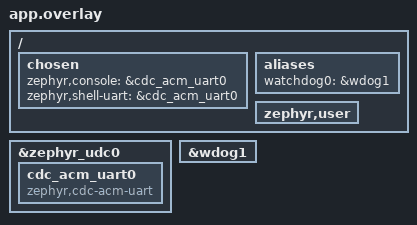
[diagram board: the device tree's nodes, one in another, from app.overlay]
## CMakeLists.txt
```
# Robotic Dog - legs firmware (Teensy 4.1, Zephyr RTOS, C++20)
cmake_minimum_required(VERSION 3.20.0)

find_package(Zephyr REQUIRED HINTS $ENV{ZEPHYR_BASE})
project(robotic_dog_legs)

# Which leg this build is for: 0=FR 1=FL 2=RR 3=RL (Conventions.md).
# scripts/02_build sets LEG_ID and the matching IP for every leg from
# scripts/legs.csv; include/config.hpp fails the build if the two disagree.
set(LEG_ID 0 CACHE STRING "Leg index 0..3 (FR FL RR RL)")

target_sources(app PRIVATE
    src/main.cpp
    src/shared.cpp
    src/hal.cpp
    src/rx_thread.cpp
    src/control_thread.cpp
    src/tx_thread.cpp
    src/supervisor_thread.cpp
)
target_include_directories(app PRIVATE include)
target_compile_definitions(app PRIVATE LEG_ID=${LEG_ID})
```

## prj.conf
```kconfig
# Robotic Dog - legs firmware configuration (Teensy 4.1, Zephyr v4.4)

# ---- C++20 --------------------------------------------------------------------
CONFIG_CPP=y
CONFIG_STD_CPP20=y
# Full C++ standard library: std::array, std::span, std::atomic, <algorithm>, ...
CONFIG_REQUIRES_FULL_LIBCPP=y

# ---- Floating point -----------------------------------------------------------
# The Teensy 4.1 board leaves the hardware FPU off; without this, float math is
# done in software. FPU_SHARING saves FPU registers when threads switch (the
# control and supervisor threads both use floats).
CONFIG_FPU=y
CONFIG_FPU_SHARING=y

# ---- Console over the Teensy's USB cable (shows up as a COM port) --------------
# printk() and log output go here. Same settings as Zephyr's cdc-acm-console
# snippet; app.overlay points the console at this USB serial port instead of the
# board's default console UART.
CONFIG_USB_DEVICE_STACK_NEXT=y
CONFIG_CDC_ACM_SERIAL_INITIALIZE_AT_BOOT=y
CONFIG_SERIAL=y
CONFIG_CONSOLE=y
CONFIG_UART_CONSOLE=y
CONFIG_UART_LINE_CTRL=y
# This USB port also carries the log output, so its own driver can't log (it
# would loop). Zephyr turns that log off anyway and warns at build time; saying
# it here silences the warning.
CONFIG_USBD_CDC_ACM_LOG_LEVEL_OFF=y

# ---- Networking: static IPv4, no DHCP (Conventions.md) -------------------------
# scripts/02_build builds one firmware per leg and overrides the address (and
# LEG_ID) from scripts/legs.csv. The default below is Front Right, LEG_ID 0.
CONFIG_NETWORKING=y
CONFIG_NET_IPV4=y
CONFIG_NET_IPV6=n
CONFIG_NET_UDP=y
CONFIG_NET_SOCKETS=y
CONFIG_NET_CONFIG_SETTINGS=y
CONFIG_NET_CONFIG_NEED_IPV4=y
CONFIG_NET_CONFIG_MY_IPV4_ADDR="192.168.1.11"
CONFIG_NET_CONFIG_MY_IPV4_NETMASK="255.255.255.0"
CONFIG_NET_DHCPV4=n
# Don't block boot waiting for the Ethernet link (default is 30 s). Zephyr
# assigns the static address whether or not the wait finishes, so with a
# static IP there is nothing to wait for: traffic flows once the link is up.
CONFIG_NET_CONFIG_INIT_TIMEOUT=0

# ---- Peripherals ---------------------------------------------------------------
# Until app.overlay enables a PWM node, CMake prints "No SOURCES given to Zephyr
# library: drivers__pwm". That warning is harmless.
CONFIG_ADC=y
CONFIG_PWM=y
CONFIG_WATCHDOG=y

# ---- Diagnostics ---------------------------------------------------------------
# INIT_STACKS + THREAD_STACK_INFO power the supervisor's stack-margin check on
# its four threads (k_thread_stack_space_get).
CONFIG_LOG=y
CONFIG_THREAD_STACK_INFO=y
CONFIG_INIT_STACKS=y

# ---- Stacks --------------------------------------------------------------------
CONFIG_MAIN_STACK_SIZE=4096
CONFIG_SYSTEM_WORKQUEUE_STACK_SIZE=2048
```

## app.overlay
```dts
/*
 * Robotic Dog - legs firmware devicetree overlay (Teensy 4.1)
 *
 * The only overlay this app uses. (Zephyr ignores app.overlay whenever a
 * boards/<board>.overlay exists, so keep everything in this one file.)
 *
 * 1. USB console: sends the Zephyr console (printk + logging) to a USB serial
 *    port on the Teensy's micro-USB connector instead of the board's default
 *    console UART (pin table: Zephyr's Teensy 4 board documentation).
 *    Same as Zephyr's cdc-acm-console snippet.
 * 2. Hardware watchdog for the supervisor's deadman (src/hal.cpp).
 * 3. Sensor and servo pins (TEMPLATE, switched off): src/hal.cpp reads them
 *    from the zephyr,user node below. While LEG_PINS_WIRED is 0, the HAL
 *    builds with stubbed sensors/outputs and logs a warning at boot.
 */

/* Set to 1 once the leg is wired like section 3 at the end of this file (edit
 * the pins there first if the real wiring differs), then do a clean build. */
#ifndef LEG_PINS_WIRED
#define LEG_PINS_WIRED 0
#endif

/ {
	chosen {
		zephyr,console = &cdc_acm_uart0;
		zephyr,shell-uart = &cdc_acm_uart0;
	};

	aliases {
		/* i.MX RT1062 WDOG2 (label wdog1) for the supervisor deadman. */
		watchdog0 = &wdog1;
	};

	zephyr,user {
#if LEG_PINS_WIRED
		/* io-channels: 6 ADC inputs - [0..2] position tilt, hip, knee;
		 *                             [3..5] current   tilt, hip, knee
		 * pwms:        3 servo outputs - tilt, hip, knee (50 Hz frame) */
		io-channels = <&adc1 7>, <&adc1 8>, <&adc1 12>,
			      <&adc1 11>, <&adc1 6>, <&adc1 5>;
		pwms = <&flexpwm2_pwm0 0 PWM_HZ(50) PWM_POLARITY_NORMAL>,
		       <&flexpwm2_pwm1 0 PWM_HZ(50) PWM_POLARITY_NORMAL>,
		       <&flexpwm2_pwm2 0 PWM_HZ(50) PWM_POLARITY_NORMAL>;
#endif
	};
};

&zephyr_udc0 {
	cdc_acm_uart0: cdc_acm_uart0 {
		compatible = "zephyr,cdc-acm-uart";
	};
};

/* Zephyr's SoC file ships both WDOGs disabled; the deadman needs this one on.
 * (Its driver accepts timeouts from 500 ms up, in 0.5 s steps.) */
&wdog1 {
	status = "okay";
};

/* ---- 3. Sensor and servo pins (example wiring) ------------------------------
 *
 * Sensors: Teensy pins 14-19 (A0-A5) = ADC1 inputs 7, 8, 12, 11, 6, 5. The
 *   numbers in io-channels and channel@N are ADC inputs, not Teensy pins.
 *   Pins 18/19 are also the I2C bus (Wire); if the leg needs I2C, use A6-A9
 *   instead (pins 20-23 = inputs 15, 0, 13, 14). Each input needs a channel@N
 *   node, or adc_channel_setup_dt() fails. This ADC only accepts gain 1, the
 *   internal reference and the default acquisition time.
 * Servos: Teensy pins 4, 5, 6 = FlexPWM2 submodules 0, 1, 2, output A
 *   (channel 0 in pwms). The teensy41 board routes no PWM pins, so each
 *   submodule needs its own pinctrl group.
 */
#if LEG_PINS_WIRED
#define LEG_ADC_INPUT(n)						\
	channel@n {							\
		reg = <n>;						\
		zephyr,gain = "ADC_GAIN_1";				\
		zephyr,reference = "ADC_REF_INTERNAL";			\
		zephyr,acquisition-time = <ADC_ACQ_TIME_DEFAULT>;	\
		zephyr,resolution = <12>;				\
	}

&adc1 {
	status = "okay";
	#address-cells = <1>;
	#size-cells = <0>;

	LEG_ADC_INPUT(7);	/* pin 14, A0: tilt position */
	LEG_ADC_INPUT(8);	/* pin 15, A1: hip position */
	LEG_ADC_INPUT(12);	/* pin 16, A2: knee position */
	LEG_ADC_INPUT(11);	/* pin 17, A3: tilt current */
	LEG_ADC_INPUT(6);	/* pin 18, A4: hip current */
	LEG_ADC_INPUT(5);	/* pin 19, A5: knee current */
};

&pinctrl {
	pinmux_servo_tilt: pinmux_servo_tilt {
		group0 {
			pinmux = <&iomuxc_gpio_emc_06_flexpwm2_pwma0>;	/* pin 4 */
			drive-strength = "r0-4";
			slew-rate = "slow";
			nxp,speed = "100-mhz";
		};
	};

	pinmux_servo_hip: pinmux_servo_hip {
		group0 {
			pinmux = <&iomuxc_gpio_emc_08_flexpwm2_pwma1>;	/* pin 5 */
			drive-strength = "r0-4";
			slew-rate = "slow";
			nxp,speed = "100-mhz";
		};
	};

	pinmux_servo_knee: pinmux_servo_knee {
		group0 {
			pinmux = <&iomuxc_gpio_b0_10_flexpwm2_pwma2>;	/* pin 6 */
			drive-strength = "r0-4";
			slew-rate = "slow";
			nxp,speed = "100-mhz";
		};
	};
};

&flexpwm2_pwm0 {
	status = "okay";
	pinctrl-0 = <&pinmux_servo_tilt>;
	pinctrl-names = "default";
};

&flexpwm2_pwm1 {
	status = "okay";
	pinctrl-0 = <&pinmux_servo_hip>;
	pinctrl-names = "default";
};

&flexpwm2_pwm2 {
	status = "okay";
	pinctrl-0 = <&pinmux_servo_knee>;
	pinctrl-names = "default";
};
#endif /* LEG_PINS_WIRED */
```

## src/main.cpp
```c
// Per-leg firmware entry point. The four threads (rx, control, tx,
// supervisor) are defined in their own files via K_THREAD_DEFINE and wait on
// init_done; main() brings up the hardware, starts the watchdog, then
// releases them. Boot-safe by construction: PWM outputs stay disabled until
// the master's ENABLE command arrives over the acked channel.
#include <zephyr/kernel.h>
#include <zephyr/logging/log.h>

#include "config.hpp"
#include "hal.hpp"
#include "shared.hpp"

LOG_MODULE_REGISTER(main, LOG_LEVEL_INF);

int main() {
  static constexpr const char* kLegName[4] = {"FR", "FL", "RR", "RL"};  // by LEG_ID
  LOG_INF("quadruped leg %s (id %u, ip %s) — Zephyr, 1 kHz control",
          kLegName[leg::cfg::kLegId], leg::cfg::kLegId, leg::cfg::kMyIp);

  leg::hal::disable_outputs();  // never twitch at boot

  if (!leg::hal::init())
    LOG_WRN("HAL degraded (see overlay warnings) — continuing for bench use");

  if (!leg::hal::wdt_start())
    LOG_ERR("hardware watchdog unavailable");

  // Release rx, control, tx, supervisor.
  for (int i = 0; i < 4; ++i) k_sem_give(&leg::init_done);

  LOG_INF("threads released; waiting for master heartbeat + ENABLE");
  return 0;
}
```

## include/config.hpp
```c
#pragma once
// Per-leg firmware tunables. Values mirror Conventions.md — change there first.
// LEG_ID and this leg's IP come from the build (scripts/02_build, using
// scripts/legs.csv): 0 = Front Right, 1 = Front Left, 2 = Rear Right,
// 3 = Rear Left.
#include <cstddef>
#include <cstdint>

namespace leg::cfg {

#ifndef LEG_ID
#define LEG_ID 0
#endif
inline constexpr std::uint8_t kLegId = LEG_ID;

// ---- network (static IPs; this leg's own IP is a Kconfig value) ------------
inline constexpr const char* kMasterIp   = "192.168.1.1";
inline constexpr std::uint16_t kPortRx   = 5005;  // we listen: setpoints, commands, heartbeat
inline constexpr std::uint16_t kPortTx   = 5006;  // master listens: telemetry, acks

#ifdef CONFIG_NET_CONFIG_MY_IPV4_ADDR
inline constexpr const char* kMyIp = CONFIG_NET_CONFIG_MY_IPV4_ADDR;

// Build sanity: leg N must use 192.168.1.(11 + N), on the master's subnet
// (Conventions.md). The build scripts pass LEG_ID and the IP together; if the
// two ever disagree, the build fails here instead of producing a leg that
// answers to the wrong address.
namespace detail {
constexpr int last_octet(const char* ip) {
  int v = 0;
  for (; *ip; ++ip) v = (*ip == '.') ? 0 : v * 10 + (*ip - '0');
  return v;
}
constexpr bool same_subnet24(const char* a, const char* b) {
  for (int dots = 0; *a && *b && *a == *b; ++a, ++b)
    if (*a == '.' && ++dots == 3) return true;
  return false;
}
}  // namespace detail
static_assert(detail::last_octet(kMyIp) == 11 + LEG_ID,
              "LEG_ID and IP disagree: leg N must use 192.168.1.(11 + N)");
static_assert(detail::same_subnet24(kMyIp, kMasterIp),
              "this leg's IP is not on the master's 192.168.1.x subnet");
#else
inline constexpr const char* kMyIp = "(not set)";
#endif

// ---- timing (diagram: control 1 kHz, TX ~500 Hz, supervisor tunable) -------
inline constexpr int kControlPeriodUs    = 1000;  // 1 kHz control tick
inline constexpr int kTelemetryPeriodMs  = 2;     // ~500 Hz
inline constexpr int kSupervisorDefaultMs = 50;   // tunable via command later
inline constexpr int kSupervisorMinMs     = 20;   // 50 Hz
inline constexpr int kSupervisorMaxMs     = 100;  // 10 Hz; must stay well under kWdtTimeoutMs

// ---- comms freshness (diagram: "comms fresh?") ------------------------------
inline constexpr std::uint32_t kSetpointTimeoutMs  = 50;   // hold/failsafe
inline constexpr std::uint32_t kHeartbeatTimeoutMs = 500;  // disarm

// Sender uptime (header t_ms) going backwards by more than this means the
// master restarted: sequence tracking resets instead of rejecting it.
inline constexpr std::uint32_t kRestartSlackMs = 1000;

// ---- watchdog ---------------------------------------------------------------
// Zephyr's i.MX WDOG driver rejects timeouts under 500 ms (0.5 s steps).
// The supervisor feeds every 20-100 ms, so 1 s leaves a 10x margin.
inline constexpr std::uint32_t kWdtTimeoutMs = 1000;

// ---- supervisor slow-check thresholds ---------------------------------------
inline constexpr float        kTrackingErrRad    = 0.5f;  // |pos - target| limit
inline constexpr std::int32_t kTrackingPersistMs = 500;   // must persist this long
inline constexpr std::size_t  kStackMarginBytes  = 256;   // min free stack headroom
inline constexpr int          kStackCheckEvery   = 20;    // supervisor passes (~1 s)

// ---- joints: calibration placeholders until the frame is measured ----------
// Conventions.md: master-side robot_config.yaml is the real source; the master
// will push these at ENABLE (SET_PARAM). These defaults keep v1 standalone.
struct JointCalib {
  float raw_at_zero;     // ADC counts at joint zero
  float rad_per_count;   // sign folded in
  float min_rad, max_rad;
  float current_limit_a; // hard per-tick limit
  float i2t_limit;       // supervisor sustained (A^2 * s above rated)
  float rated_a;
};
inline constexpr JointCalib kJoint[3] = {
    // tilt                                           (placeholders)
    {2048.f, 0.001534f, -0.6f, 0.6f, 3.0f, 4.0f, 1.5f},
    // hip
    {2048.f, 0.001534f, -1.2f, 1.2f, 4.0f, 6.0f, 2.0f},
    // knee
    {2048.f, 0.001534f, 0.0f, 2.4f, 4.0f, 6.0f, 2.0f},
};

// Current sensor: amps = (raw - zero) * kAmpsPerCount   (placeholder)
inline constexpr float kCurrentZeroCounts = 2048.f;
inline constexpr float kAmpsPerCount      = 0.004f;

// Servo mapping (v1: hobby servos, direct PWM; motors+PID later).
inline constexpr std::uint32_t kServoPeriodNs  = 20'000'000;  // 50 Hz frame
inline constexpr std::uint32_t kServoCenterNs  = 1'500'000;
inline constexpr float kServoNsPerRad = 1'000'000.0f / 1.5708f;  // ±90° -> ±1000 µs

}  // namespace leg::cfg
```

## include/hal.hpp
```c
#pragma once
// Hardware access: 3x position + 3x current ADC channels, 3x FlexPWM servo
// outputs. All devicetree bindings come from app.overlay; until
// the overlay has real pins, the stubs keep the logic building and testable.
#include <cstdint>

namespace leg::hal {

struct Sensors {
  float pos_rad[3];     // calibrated joint angles
  float current_a[3];   // calibrated joint currents
  bool  valid;
};

bool init();                       // ADC + PWM + watchdog devices ready?
Sensors read_sensors();            // one synchronous sample of all 6 channels

// v1 servo mode: write position targets straight to PWM (diagram:
// "servos now: direct · motors later: PID").
void write_servos(const float target_rad[3]);
void disable_outputs();            // zero pulse width = servos released

// Hardware watchdog (i.MX RT WDOG): supervisor feeds it, nobody else.
bool wdt_start();
void wdt_feed();

}  // namespace leg::hal
```

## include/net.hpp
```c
#pragma once
// Small zsock helpers shared by the RX and TX threads.
#include <zephyr/net/socket.h>

#include <cstdint>
#include <cstring>

#include "config.hpp"

namespace leg::net {

inline sockaddr_in master_endpoint() {
  sockaddr_in a{};
  a.sin_family = AF_INET;
  a.sin_port = htons(cfg::kPortTx);
  zsock_inet_pton(AF_INET, cfg::kMasterIp, &a.sin_addr);
  return a;
}

// Bound RX socket (we listen on :5005), or -1.
inline int make_rx_socket() {
  const int s = zsock_socket(AF_INET, SOCK_DGRAM, IPPROTO_UDP);
  if (s < 0) return -1;
  sockaddr_in local{};
  local.sin_family = AF_INET;
  local.sin_addr.s_addr = INADDR_ANY;
  local.sin_port = htons(cfg::kPortRx);
  if (zsock_bind(s, reinterpret_cast<sockaddr*>(&local), sizeof(local)) < 0) {
    zsock_close(s);
    return -1;
  }
  return s;
}

// Unbound TX socket for telemetry/acks toward the master.
inline int make_tx_socket() {
  return zsock_socket(AF_INET, SOCK_DGRAM, IPPROTO_UDP);
}

inline bool from_master(const sockaddr_in& from) {
  static const sockaddr_in master = master_endpoint();
  return std::memcmp(&from.sin_addr, &master.sin_addr, sizeof(in_addr)) == 0;
}

}  // namespace leg::net
```

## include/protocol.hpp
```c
#pragma once
// Wire protocol — byte-for-byte identical to the master's protocol.hpp
// (Conventions.md): little-endian packed structs, 14-byte header,
// CRC16-CCITT over header+payload, crc field last.
#include <cstdint>
#include <cstring>
#include <optional>
#include <span>

namespace leg::proto {

inline constexpr std::uint16_t kMagic   = 0xC0DE;  // fixed start marker
inline constexpr std::uint8_t  kVersion = 1;

enum class Type : std::uint8_t {
  Setpoint  = 1,
  Command   = 2,
  Heartbeat = 3,
  Telemetry = 4,
  Ack       = 5,
};

enum class Cmd : std::uint8_t {
  Enable      = 1,  // arm (refused while faults are latched)
  Disable     = 2,  // disarm
  ClearFaults = 3,  // operator acknowledged a fault; only honored while disarmed
};

#pragma pack(push, 1)
struct Header {
  std::uint16_t magic;
  std::uint8_t  version;
  std::uint8_t  type;
  std::uint8_t  leg_id;
  std::uint8_t  flags;
  std::uint32_t seq;
  std::uint32_t t_ms;
};
static_assert(sizeof(Header) == 14);

struct SetpointPacket {
  Header header;
  float  target_rad[3];
  std::uint16_t crc;
};
struct CommandPacket {
  Header header;
  std::uint8_t cmd;
  float        param;
  std::uint16_t crc;
};
struct HeartbeatPacket {
  Header header;
  std::uint8_t fsm_state;
  std::uint16_t crc;
};
struct TelemetryPacket {
  Header header;
  float pos_rad[3];
  float current_a[3];
  std::uint16_t fault_flags;
  std::uint16_t lost_packets;
  std::uint16_t crc_errors;
  std::uint8_t  armed;
  std::uint8_t  state;
  std::uint16_t crc;
};
struct AckPacket {
  Header header;
  std::uint32_t acked_seq;
  std::uint16_t crc;
};
#pragma pack(pop)

constexpr std::uint16_t crc16(std::span<const std::uint8_t> data) {
  std::uint16_t crc = 0xFFFF;
  for (std::uint8_t b : data) {
    crc ^= static_cast<std::uint16_t>(b) << 8;
    for (int i = 0; i < 8; ++i)
      crc = (crc & 0x8000) ? static_cast<std::uint16_t>((crc << 1) ^ 0x1021)
                           : static_cast<std::uint16_t>(crc << 1);
  }
  return crc;
}

template <typename P>
void seal(P& pkt) {
  auto* bytes = reinterpret_cast<std::uint8_t*>(&pkt);
  pkt.crc = crc16({bytes, sizeof(P) - sizeof(std::uint16_t)});
}

template <typename P>
std::optional<P> parse(std::span<const std::uint8_t> raw, Type expected) {
  if (raw.size() != sizeof(P)) return std::nullopt;
  P pkt;
  std::memcpy(&pkt, raw.data(), sizeof(P));
  if (pkt.header.magic != kMagic) return std::nullopt;
  if (pkt.header.version != kVersion) return std::nullopt;
  if (pkt.header.type != static_cast<std::uint8_t>(expected)) return std::nullopt;
  if (crc16(raw.first(sizeof(P) - sizeof(std::uint16_t))) != pkt.crc) return std::nullopt;
  return pkt;
}

}  // namespace leg::proto
```

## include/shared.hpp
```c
#pragma once
// The green boxes from the leg diagram — the ONLY places data crosses
// threads. Nothing on the hot path blocks or sleeps.
//
//   setpoint slot   spinlock copy, latest wins  RX  -> control
//   command queue   k_msgq, depth 8             RX  -> control
//   state snapshot  double buffer               control -> TX
//   health flag     atomic, set every tick      control -> supervisor
//   loss/CRC counters, t_hBeat, t_setpoint      atomics, RX writes
#include <zephyr/kernel.h>

#include <atomic>
#include <cstdint>

namespace leg {

// ---- setpoint slot (latest wins) -------------------------------------------
struct Setpoints {
  float target_rad[3]{};
};

// The RX thread writes; the control and supervisor threads read. On this
// single-core chip a k_spinlock just masks interrupts for the 12-byte copy, so
// no thread can be preempted halfway through it and nobody ever waits. (A
// seqlock is wrong here: if the 1 kHz tick preempted the RX thread mid-write,
// the higher-priority control thread spun forever on a write the RX thread
// could never get the CPU to finish.)
class SetpointSlot {
 public:
  void store(const Setpoints& s) {
    const k_spinlock_key_t key = k_spin_lock(&lock_);
    value_ = s;
    k_spin_unlock(&lock_, key);
  }
  Setpoints load() const {
    const k_spinlock_key_t key = k_spin_lock(&lock_);
    const Setpoints out = value_;
    k_spin_unlock(&lock_, key);
    return out;
  }

 private:
  mutable k_spinlock lock_{};  // zero-initialized = unlocked
  Setpoints value_{};
};

// ---- command queue (k_msgq is defined in shared.cpp, depth 8) --------------
struct CmdMsg {
  std::uint8_t  cmd;    // proto::Cmd
  float         param;
  std::uint32_t seq;    // echoed in the ACK
};
extern k_msgq cmd_queue;

// ---- state snapshot (double buffer: control writes, TX reads) --------------
struct Snapshot {
  float pos_rad[3]{};
  float current_a[3]{};
  std::uint16_t fault_flags{};
  std::uint8_t  armed{};
  std::uint8_t  state{};   // LegState below
};

class SnapshotBuffer {
 public:
  void publish(const Snapshot& s) {
    const int next = 1 - active_.load(std::memory_order_relaxed);
    buf_[next] = s;
    active_.store(next, std::memory_order_release);
  }
  Snapshot read() const {
    return buf_[active_.load(std::memory_order_acquire)];
  }

 private:
  Snapshot buf_[2]{};
  std::atomic<int> active_{0};
};

// ---- timestamps ------------------------------------------------------------
// Milliseconds from k_uptime_get_32(). 32-bit on purpose: the Cortex-M7 has no
// 64-bit atomics, so std::atomic<int64_t> fails to link (__atomic_load_8).
// Unsigned subtraction keeps ages right across the 49.7-day wraparound; always
// go through age_ms() so the math stays 32-bit unsigned.
constexpr std::uint32_t age_ms(std::uint32_t now, std::uint32_t then) {
  return now - then;
}
// "Never received": starts about 24 days in the past, so nothing is fresh
// until the first packet arrives.
inline constexpr std::uint32_t kNeverMs = 0x8000'0000u;

// ---- atomics shared across threads -----------------------------------------
struct SharedState {
  SetpointSlot   setpoints;
  SnapshotBuffer snapshot;

  std::atomic<std::uint32_t> t_setpoint_ms{kNeverMs};  // last valid setpoint
  std::atomic<std::uint32_t> t_hbeat_ms{kNeverMs};     // last heartbeat (t_hBeat)
  std::atomic<bool>         armed{false};
  std::atomic<bool>         health_flag{false};         // control sets, supervisor clears
  std::atomic<std::uint16_t> fault_flags{0};            // supervisor-latched faults

  // link stats: RX writes, TX reports, supervisor watches the trend
  std::atomic<std::uint16_t> lost_packets{0};
  std::atomic<std::uint16_t> crc_errors{0};
  std::atomic<std::uint32_t> rx_ok{0};

  std::atomic<std::int32_t>  supervisor_period_ms{0};   // 0 -> use default
};
extern SharedState g;

// Startup gate: main() gives this 4 times once HAL + watchdog are up.
extern k_sem init_done;

// The four application threads (K_THREAD_DEFINE in their own .cpp files).
// The supervisor's stack check watches these.
extern const k_tid_t rx_tid;
extern const k_tid_t control_tid;
extern const k_tid_t tx_tid;
extern const k_tid_t supervisor_tid;

// Fault bits (telemetry fault_flags)
inline constexpr std::uint16_t kFaultOverCurrent = 1u << 0;
inline constexpr std::uint16_t kFaultRange       = 1u << 1;
inline constexpr std::uint16_t kFaultCommsLost   = 1u << 2;
inline constexpr std::uint16_t kFaultI2t         = 1u << 3;
inline constexpr std::uint16_t kFaultTracking    = 1u << 4;
inline constexpr std::uint16_t kFaultStack       = 1u << 5;

enum class LegState : std::uint8_t { Disarmed = 0, Armed = 1, Failsafe = 2 };

}  // namespace leg
```

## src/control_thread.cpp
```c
// Diagram: "Control thread (1 kHz, prio high)".
//   k_sem_take(tick) <- k_timer ISR @ 1 kHz
//   read sensors -> copy setpoints + drain commands -> comms fresh?
//   (setpoint < 50 ms, heartbeat < 500 ms) -> failsafe/disarm
//   per-tick checks (armed? I > limit? pos in range?) -> targets -> FlexPWM
//   publish snapshot + set health flag -> loop
#include <zephyr/kernel.h>
#include <zephyr/logging/log.h>

#include <algorithm>

#include "config.hpp"
#include "hal.hpp"
#include "protocol.hpp"
#include "shared.hpp"

LOG_MODULE_REGISTER(control, LOG_LEVEL_INF);

namespace leg {
namespace {

K_SEM_DEFINE(tick_sem, 0, 1);

void tick_isr(k_timer*) { k_sem_give(&tick_sem); }  // ISR: capture + signal only
K_TIMER_DEFINE(tick_timer, tick_isr, nullptr);

// Returns true when an ENABLE armed the leg this tick, so the caller can
// re-seed targets from the measured pose (motionless arming).
bool drain_commands() {
  bool just_armed = false;
  CmdMsg msg;
  while (k_msgq_get(&cmd_queue, &msg, K_NO_WAIT) == 0) {
    switch (static_cast<proto::Cmd>(msg.cmd)) {
      case proto::Cmd::Enable:
        // Faults clear only through an operator-acknowledged CLEAR_FAULTS,
        // never as a side effect of arming.
        if (const auto f = g.fault_flags.load(); f != 0) {
          LOG_WRN("ENABLE refused: latched faults 0x%04x (cmd seq %u)", f, msg.seq);
          break;
        }
        if (!g.armed.exchange(true)) just_armed = true;
        LOG_INF("ENABLE (cmd seq %u)", msg.seq);
        break;
      case proto::Cmd::Disable:
        g.armed.store(false);
        LOG_INF("DISABLE (cmd seq %u)", msg.seq);
        break;
      case proto::Cmd::ClearFaults:
        if (g.armed.load()) {
          LOG_WRN("CLEAR_FAULTS ignored while armed (cmd seq %u)", msg.seq);
          break;
        }
        g.fault_flags.store(0);  // a still-present cause re-latches on its next check
        LOG_INF("faults cleared by operator (cmd seq %u)", msg.seq);
        break;
    }
  }
  return just_armed;
}

void control_main(void*, void*, void*) {
  k_sem_take(&init_done, K_FOREVER);
  k_timer_start(&tick_timer, K_USEC(cfg::kControlPeriodUs),
                K_USEC(cfg::kControlPeriodUs));
  LOG_INF("control loop at %d us", cfg::kControlPeriodUs);

  float targets[3] = {0.f, 0.f, 0.f};  // last good targets (hold on brief gaps)

  for (;;) {
    k_sem_take(&tick_sem, K_FOREVER);
    const std::uint32_t now_ms = k_uptime_get_32();

    // 1. sensors: 3x position, 3x current
    const hal::Sensors s = hal::read_sensors();

    // 2. latest setpoints + any pending commands
    const Setpoints sp = g.setpoints.load();
    const bool just_armed = drain_commands();

    // Motionless arming: the instant ENABLE lands, seed targets from the
    // MEASURED joint positions so the servos hold where the leg already is
    // instead of snapping to the zero pose. The master's stand-up ramp also
    // starts from the reported pose, so the first setpoints match this.
    if (just_armed && s.valid) {
      targets[0] = s.pos_rad[0];
      targets[1] = s.pos_rad[1];
      targets[2] = s.pos_rad[2];
    }

    // 3. comms fresh?  setpoint < 50 ms (hold), heartbeat < 500 ms (disarm)
    const bool sp_fresh =
        age_ms(now_ms, g.t_setpoint_ms.load()) < cfg::kSetpointTimeoutMs;
    const bool hb_fresh =
        age_ms(now_ms, g.t_hbeat_ms.load()) < cfg::kHeartbeatTimeoutMs;

    bool armed = g.armed.load();
    LegState state = armed ? LegState::Armed : LegState::Disarmed;

    if (armed && !hb_fresh) {           // master silent: failsafe / disarm
      g.armed.store(false);
      armed = false;
      state = LegState::Failsafe;
      g.fault_flags.fetch_or(kFaultCommsLost);
      LOG_WRN("heartbeat lost -> disarm");
    } else if (armed && sp_fresh) {
      targets[0] = sp.target_rad[0];
      targets[1] = sp.target_rad[1];
      targets[2] = sp.target_rad[2];
    }
    // armed && !sp_fresh: hold last targets (brief gap costs one stale tick)

    // 4. per-tick checks: cheap compares only — the expensive ones live in
    //    the supervisor. Range clamps the target; overcurrent latches fault.
    std::uint16_t faults = 0;
    for (int i = 0; i < 3; ++i) {
      const auto& c = cfg::kJoint[i];
      if (targets[i] < c.min_rad || targets[i] > c.max_rad) {
        targets[i] = std::clamp(targets[i], c.min_rad, c.max_rad);
        faults |= kFaultRange;
      }
      if (s.valid && s.current_a[i] > c.current_limit_a)
        faults |= kFaultOverCurrent;
    }
    if (faults & kFaultOverCurrent) {   // hard limit: cut now, stay cut
      g.armed.store(false);
      armed = false;
      g.fault_flags.fetch_or(faults);
    }

    // 5. outputs: servos now (direct), motors later (PID goes right here)
    if (armed) hal::write_servos(targets);
    else hal::disable_outputs();

    // 6. publish snapshot for TX, set health flag for the supervisor
    Snapshot snap{};
    for (int i = 0; i < 3; ++i) {
      snap.pos_rad[i] = s.pos_rad[i];
      snap.current_a[i] = s.current_a[i];
    }
    snap.fault_flags = g.fault_flags.load() | faults;
    snap.armed = armed ? 1 : 0;
    snap.state = static_cast<std::uint8_t>(state);
    g.snapshot.publish(snap);
    g.health_flag.store(true);          // supervisor feeds WDOG only on this
  }
}

}  // namespace

// Outside the anonymous namespace so shared.hpp's control_tid names this thread.
K_THREAD_DEFINE(control_tid, 4096, control_main, NULL, NULL, NULL, 2, 0, 0);

}  // namespace leg
```

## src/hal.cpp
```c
// Devicetree-backed HAL. Channels/pins come from the zephyr,user node in
// app.overlay. Guarded so the code still compiles while the
// overlay is a template — stubbed paths log once and return safe values.
#include "hal.hpp"

#include <zephyr/device.h>
#include <zephyr/drivers/adc.h>
#include <zephyr/drivers/pwm.h>
#include <zephyr/drivers/watchdog.h>
#include <zephyr/kernel.h>
#include <zephyr/logging/log.h>

#include <algorithm>

#include "config.hpp"

LOG_MODULE_REGISTER(hal, LOG_LEVEL_INF);

namespace leg::hal {
namespace {

#define USER_NODE DT_PATH(zephyr_user)

#if DT_NODE_HAS_PROP(USER_NODE, io_channels)
constexpr bool kHasAdc = true;
const adc_dt_spec adc_ch[6] = {
    ADC_DT_SPEC_GET_BY_IDX(USER_NODE, 0), ADC_DT_SPEC_GET_BY_IDX(USER_NODE, 1),
    ADC_DT_SPEC_GET_BY_IDX(USER_NODE, 2), ADC_DT_SPEC_GET_BY_IDX(USER_NODE, 3),
    ADC_DT_SPEC_GET_BY_IDX(USER_NODE, 4), ADC_DT_SPEC_GET_BY_IDX(USER_NODE, 5),
};
#else
constexpr bool kHasAdc = false;
#endif

#if DT_NODE_HAS_PROP(USER_NODE, pwms)
constexpr bool kHasPwm = true;
const pwm_dt_spec servo[3] = {
    PWM_DT_SPEC_GET_BY_IDX(USER_NODE, 0),
    PWM_DT_SPEC_GET_BY_IDX(USER_NODE, 1),
    PWM_DT_SPEC_GET_BY_IDX(USER_NODE, 2),
};
#else
constexpr bool kHasPwm = false;
#endif

// A node can exist but be disabled (Zephyr ships both i.MX WDOGs disabled),
// and DEVICE_DT_GET on a disabled node fails at link time — so require
// status "okay", which the overlay sets.
#define LEG_HAS_WDT DT_NODE_HAS_STATUS(DT_ALIAS(watchdog0), okay)

#if LEG_HAS_WDT
const device* wdt_dev = DEVICE_DT_GET(DT_ALIAS(watchdog0));
int wdt_channel = -1;
#endif

#if DT_NODE_HAS_PROP(USER_NODE, io_channels)
float counts_to_rad(int joint, float raw) {
  const auto& c = cfg::kJoint[joint];
  return (raw - c.raw_at_zero) * c.rad_per_count;
}
#endif

}  // namespace

bool init() {
  bool ok = true;
#if DT_NODE_HAS_PROP(USER_NODE, io_channels)
  for (const auto& ch : adc_ch) {
    if (!adc_is_ready_dt(&ch)) { LOG_ERR("ADC channel not ready"); ok = false; }
    else if (adc_channel_setup_dt(&ch) != 0) {
      LOG_ERR("ADC channel %u setup failed (check its channel@ node in app.overlay)",
              ch.channel_id);
      ok = false;
    }
  }
#else
  LOG_WRN("overlay has no io-channels: sensor reads are STUBBED");
#endif
#if DT_NODE_HAS_PROP(USER_NODE, pwms)
  for (const auto& s : servo)
    if (!pwm_is_ready_dt(&s)) { LOG_ERR("PWM channel not ready"); ok = false; }
#else
  LOG_WRN("overlay has no pwms: servo outputs are STUBBED");
#endif
  return ok;
}

Sensors read_sensors() {
  Sensors out{};
#if DT_NODE_HAS_PROP(USER_NODE, io_channels)
  std::int16_t sample = 0;
  adc_sequence seq{};  // adc_sequence_init_dt fills channels/resolution
  seq.buffer = &sample;
  seq.buffer_size = sizeof(sample);
  for (int i = 0; i < 6; ++i) {
    adc_sequence_init_dt(&adc_ch[i], &seq);
    if (adc_read(adc_ch[i].dev, &seq) != 0) return out;  // valid stays false
    const float raw = static_cast<float>(sample);
    if (i < 3) out.pos_rad[i] = counts_to_rad(i, raw);
    else out.current_a[i - 3] = (raw - cfg::kCurrentZeroCounts) * cfg::kAmpsPerCount;
  }
  out.valid = true;
#else
  out.valid = true;  // stub: zeros, so the state machine still runs on a bench
#endif
  return out;
}

void write_servos(const float target_rad[3]) {
#if DT_NODE_HAS_PROP(USER_NODE, pwms)
  for (int i = 0; i < 3; ++i) {
    const float ns = static_cast<float>(cfg::kServoCenterNs) +
                     target_rad[i] * cfg::kServoNsPerRad;
    const auto pulse = static_cast<std::uint32_t>(
        std::clamp(ns, 500'000.0f, 2'500'000.0f));
    pwm_set_pulse_dt(&servo[i], pulse);
  }
#else
  ARG_UNUSED(target_rad);
#endif
}

void disable_outputs() {
#if DT_NODE_HAS_PROP(USER_NODE, pwms)
  for (const auto& s : servo) pwm_set_pulse_dt(&s, 0);  // released, not driven
#endif
}

bool wdt_start() {
#if LEG_HAS_WDT
  if (!device_is_ready(wdt_dev)) { LOG_ERR("watchdog not ready"); return false; }
  wdt_timeout_cfg tcfg{
      .window = {.min = 0, .max = cfg::kWdtTimeoutMs},
      .callback = nullptr,
      .flags = WDT_FLAG_RESET_SOC,
  };
  wdt_channel = wdt_install_timeout(wdt_dev, &tcfg);
  if (wdt_channel < 0) {
    LOG_ERR("wdt_install_timeout(%u ms) failed: %d", cfg::kWdtTimeoutMs, wdt_channel);
    return false;
  }
  const int rc = wdt_setup(wdt_dev, WDT_OPT_PAUSE_HALTED_BY_DBG);
  if (rc != 0) {
    LOG_ERR("wdt_setup failed: %d", rc);
    return false;
  }
  LOG_INF("hardware watchdog armed: %u ms", cfg::kWdtTimeoutMs);
  return true;
#else
  LOG_WRN("watchdog0 alias missing or disabled: HW watchdog OFF (bench mode)");
  return true;
#endif
}

void wdt_feed() {
#if LEG_HAS_WDT
  if (wdt_channel >= 0) ::wdt_feed(wdt_dev, wdt_channel);
#endif
}

}  // namespace leg::hal
```

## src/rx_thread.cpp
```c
// Diagram: "Net RX thread (prio mid)".
//   recvfrom(:5005) -> magic+CRC ok? -> seq > last_seq? -> count gaps ->
//   dispatch: setpoints -> slot, commands -> k_msgq (+ACK), heartbeat -> t_hBeat
//
// Two rules keep the sequence check from deafening the leg:
//   * Restart-aware: if the master's uptime (header t_ms) jumps backwards,
//     the master restarted and sequence tracking starts over.
//   * Commands are never dropped as "old": a retransmitted command carries
//     its original sequence number, which newer setpoints may already have
//     overtaken. Commands are de-duplicated by their own sequence instead.
#include <zephyr/kernel.h>
#include <zephyr/logging/log.h>
#include <zephyr/net/socket.h>

#include <cstdint>
#include <span>

#include "config.hpp"
#include "net.hpp"
#include "protocol.hpp"
#include "shared.hpp"

LOG_MODULE_REGISTER(rx, LOG_LEVEL_INF);

namespace leg {
namespace {

std::uint32_t last_seq = 0;        // newest master packet seen this session
std::uint32_t last_cmd_seq = 0;    // newest command already queued
std::uint32_t last_master_t = 0;   // newest master uptime seen (ms)
bool          have_master_t = false;
std::uint32_t ack_seq = 0;

void send_ack(int tx_sock, std::uint32_t acked, std::uint32_t t_ms) {
  proto::AckPacket p{
      .header = {.magic = proto::kMagic,
                 .version = proto::kVersion,
                 .type = static_cast<std::uint8_t>(proto::Type::Ack),
                 .leg_id = cfg::kLegId,
                 .flags = 0,
                 .seq = ++ack_seq,
                 .t_ms = t_ms},
      .acked_seq = acked,
      .crc = 0};
  proto::seal(p);
  const sockaddr_in master = net::master_endpoint();
  zsock_sendto(tx_sock, &p, sizeof(p), 0,
               reinterpret_cast<const sockaddr*>(&master), sizeof(master));
}

// Every header carries the sender's uptime. A backwards jump larger than
// kRestartSlackMs means a new master session: forget the old sequence
// numbers instead of rejecting the new session for as long as the old ran.
void track_master_session(const proto::Header& h) {
  if (have_master_t && h.t_ms + cfg::kRestartSlackMs < last_master_t) {
    LOG_WRN("master restart detected (uptime %u -> %u ms): sequence tracking reset",
            last_master_t, h.t_ms);
    last_seq = 0;
    last_cmd_seq = 0;
    last_master_t = h.t_ms;
  } else if (!have_master_t || h.t_ms > last_master_t) {
    last_master_t = h.t_ms;
  }
  have_master_t = true;
}

// Records seq if it is the newest seen, counting any gap as lost packets.
// Returns false for duplicates and reordered (older) packets.
bool record_seq(std::uint32_t seq) {
  if (last_seq != 0 && seq <= last_seq) return false;
  if (last_seq != 0 && seq > last_seq + 1)
    g.lost_packets.fetch_add(static_cast<std::uint16_t>(seq - last_seq - 1));
  last_seq = seq;
  return true;
}

void dispatch(std::span<const std::uint8_t> raw, int tx_sock) {
  const std::uint32_t now_ms = k_uptime_get_32();

  // Streams (setpoints, heartbeats): newest wins, older packets are stale.
  if (auto p = proto::parse<proto::SetpointPacket>(raw, proto::Type::Setpoint)) {
    if (p->header.leg_id != cfg::kLegId) return;
    track_master_session(p->header);
    if (!record_seq(p->header.seq)) return;
    g.setpoints.store(Setpoints{{p->target_rad[0], p->target_rad[1], p->target_rad[2]}});
    g.t_setpoint_ms.store(now_ms);
    g.rx_ok.fetch_add(1);
    return;
  }
  if (auto p = proto::parse<proto::HeartbeatPacket>(raw, proto::Type::Heartbeat)) {
    if (p->header.leg_id != cfg::kLegId) return;
    track_master_session(p->header);
    if (!record_seq(p->header.seq)) return;
    g.t_hbeat_ms.store(now_ms);   // t_hBeat: master is alive (any FSM state)
    g.rx_ok.fetch_add(1);
    return;
  }

  // Commands: never rejected as old; de-duplicated by command sequence.
  if (auto p = proto::parse<proto::CommandPacket>(raw, proto::Type::Command)) {
    if (p->header.leg_id != cfg::kLegId) return;
    track_master_session(p->header);
    const std::uint32_t seq = p->header.seq;
    record_seq(seq);  // loss statistics only
    if (seq <= last_cmd_seq) {          // retransmit of a command already queued
      send_ack(tx_sock, seq, now_ms);   // our earlier ACK was lost: re-ACK
      return;
    }
    CmdMsg msg{.cmd = p->cmd, .param = p->param, .seq = seq};
    if (k_msgq_put(&cmd_queue, &msg, K_NO_WAIT) != 0) {
      LOG_WRN("command queue full: cmd %u not ACKed, master will retry", msg.cmd);
      return;
    }
    last_cmd_seq = seq;
    send_ack(tx_sock, seq, now_ms);     // ACK only once the command is queued
    g.rx_ok.fetch_add(1);
    return;
  }
  g.crc_errors.fetch_add(1);  // wrong magic/CRC/size: drop, count
}

void rx_main(void*, void*, void*) {
  k_sem_take(&init_done, K_FOREVER);

  const int rx = net::make_rx_socket();
  const int tx = net::make_tx_socket();
  if (rx < 0 || tx < 0) {
    LOG_ERR("socket setup failed (rx=%d tx=%d)", rx, tx);
    return;
  }
  LOG_INF("listening on :%u as leg %u", cfg::kPortRx, cfg::kLegId);

  std::uint8_t buf[128];
  for (;;) {
    sockaddr_in from{};
    socklen_t from_len = sizeof(from);
    const auto n = zsock_recvfrom(rx, buf, sizeof(buf), 0,
                                  reinterpret_cast<sockaddr*>(&from), &from_len);
    if (n <= 0) continue;
    if (!net::from_master(from)) continue;  // only the master may command us
    dispatch({buf, static_cast<std::size_t>(n)}, tx);
  }
}

}  // namespace

// Outside the anonymous namespace so shared.hpp's rx_tid names this thread.
K_THREAD_DEFINE(rx_tid, 4096, rx_main, NULL, NULL, NULL, 5, 0, 0);

}  // namespace leg
```

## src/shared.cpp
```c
// Definitions of the shared objects declared in shared.hpp.
#include "shared.hpp"

namespace leg {

// Diagram: "command queue — k_msgq, depth 8".
K_MSGQ_DEFINE(cmd_queue, sizeof(CmdMsg), 8, 4);

SharedState g;

// Gate: main() releases the worker threads once HAL + watchdog are up.
K_SEM_DEFINE(init_done, 0, 4);

}  // namespace leg
```

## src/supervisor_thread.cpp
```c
// Diagram: "Supervisor (10–50 Hz, tunable)".
//   k_sleep(cfg.period) -> slow checks (I²t window, tracking error,
//   link loss trend, stack margins) -> on fault: flag telemetry, disarm ->
//   health flag fresh? -> feed WDOG / don't feed -> HW reset
#include <zephyr/kernel.h>
#include <zephyr/logging/log.h>

#include <algorithm>
#include <cmath>

#include "config.hpp"
#include "hal.hpp"
#include "shared.hpp"

LOG_MODULE_REGISTER(supervisor, LOG_LEVEL_INF);

namespace leg {
namespace {

void supervisor_main(void*, void*, void*) {
  k_sem_take(&init_done, K_FOREVER);
  LOG_INF("supervisor at %d ms (tunable)", cfg::kSupervisorDefaultMs);

  float i2t_acc[3] = {0.f, 0.f, 0.f};
  std::uint16_t last_lost = 0;
  std::int32_t tracking_err_ms = 0;
  [[maybe_unused]] int pass = 0;

  for (;;) {
    // Clamped to 10-50 Hz so no tuned value can starve the watchdog.
    const std::int32_t override_ms = g.supervisor_period_ms.load();
    const std::int32_t period_ms =
        std::clamp(override_ms > 0 ? override_ms : cfg::kSupervisorDefaultMs,
                   cfg::kSupervisorMinMs, cfg::kSupervisorMaxMs);
    k_sleep(K_MSEC(period_ms));
    const float dt = static_cast<float>(period_ms) / 1000.f;

    const Snapshot snap = g.snapshot.read();
    std::uint16_t faults = 0;

    // I²t window: a motor survives brief spikes but not sustained overload.
    for (int i = 0; i < 3; ++i) {
      const auto& c = cfg::kJoint[i];
      const float i2 = snap.current_a[i] * snap.current_a[i];
      const float rated2 = c.rated_a * c.rated_a;
      i2t_acc[i] = std::max(0.f, i2t_acc[i] + (i2 - rated2) * dt);
      if (i2t_acc[i] > c.i2t_limit) faults |= kFaultI2t;
    }

    // Tracking error must PERSIST (diagram: "tracking error persists?") —
    // one bad sample during a foot strike is normal; half a second of the
    // joint ignoring its target means jammed or broken.
    const Setpoints sp = g.setpoints.load();
    bool erring = false;
    if (snap.armed) {
      for (int i = 0; i < 3; ++i)
        if (std::abs(snap.pos_rad[i] - sp.target_rad[i]) > cfg::kTrackingErrRad)
          erring = true;
    }
    tracking_err_ms = erring ? tracking_err_ms + period_ms : 0;
    if (tracking_err_ms >= cfg::kTrackingPersistMs) faults |= kFaultTracking;

    // Link loss trend: on a healthy dedicated switch this stays zero, so a
    // rising counter is a bug/cable to investigate, not noise to tolerate.
    const std::uint16_t lost = g.lost_packets.load();
    if (lost != last_lost)
      LOG_WRN("packet loss rising: %u total", lost);
    last_lost = lost;

    // Stack margins (diagram: "stack margins"): about once a second, flag any
    // of OUR four threads with less than kStackMarginBytes of stack left.
    // Zephyr's own threads are left out on purpose: it sizes them tightly
    // (the idle thread has 320 bytes in total), so a fixed margin would fault
    // a healthy leg, and the MPU stack guard (CONFIG_MPU_STACK_GUARD) already
    // catches a real overflow in any thread. The scan runs with interrupts
    // enabled, so it cannot delay the 1 kHz control tick.
#ifdef CONFIG_INIT_STACKS
    if (++pass % cfg::kStackCheckEvery == 0) {
      static constexpr const char* kName[] = {"rx", "control", "tx", "supervisor"};
      const k_tid_t tids[] = {rx_tid, control_tid, tx_tid, supervisor_tid};
      for (int i = 0; i < 4; ++i) {
        std::size_t unused = 0;
        if (k_thread_stack_space_get(tids[i], &unused) == 0 &&
            unused < cfg::kStackMarginBytes) {
          faults |= kFaultStack;
          LOG_ERR("%s thread stack nearly full: %u bytes left", kName[i],
                  static_cast<unsigned>(unused));
        }
      }
    }
#endif

    if (faults) {
      g.fault_flags.fetch_or(faults);   // flagged in telemetry
      g.armed.store(false);             // derate/disable the leg
      LOG_ERR("supervisor fault 0x%04x -> disarm", faults);
    }

    // Deadman: feed the hardware watchdog ONLY if the control thread set its
    // health flag since our last pass. A hung control loop starves the WDOG
    // and the i.MX RT resets — a reset leg is safer than a frozen one.
    if (g.health_flag.exchange(false)) {
      hal::wdt_feed();
    } else {
      LOG_ERR("control thread unresponsive: letting WDOG starve");
      // no feed -> hardware reset within cfg::kWdtTimeoutMs
    }
  }
}

}  // namespace

// Outside the anonymous namespace so shared.hpp's supervisor_tid names this thread.
K_THREAD_DEFINE(supervisor_tid, 2048, supervisor_main, NULL, NULL, NULL, 9, 0, 0);

}  // namespace leg
```

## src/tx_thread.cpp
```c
// Diagram: "Telemetry TX thread (prio low)".
//   k_sleep(2 ms) -> copy snapshot + link stats -> build packet
//   (seq++ · timestamp · CRC16) -> sendto(master :5006) -> loop
#include <zephyr/kernel.h>
#include <zephyr/logging/log.h>
#include <zephyr/net/socket.h>

#include <cstdint>

#include "config.hpp"
#include "net.hpp"
#include "protocol.hpp"
#include "shared.hpp"

LOG_MODULE_REGISTER(tx, LOG_LEVEL_INF);

namespace leg {
namespace {

void tx_main(void*, void*, void*) {
  k_sem_take(&init_done, K_FOREVER);

  const int sock = net::make_tx_socket();
  if (sock < 0) {
    LOG_ERR("tx socket failed");
    return;
  }
  const sockaddr_in master = net::master_endpoint();
  LOG_INF("telemetry -> %s:%u every %d ms", cfg::kMasterIp, cfg::kPortTx,
          cfg::kTelemetryPeriodMs);

  std::uint32_t seq = 0;
  for (;;) {
    const Snapshot snap = g.snapshot.read();

    proto::TelemetryPacket p{
        .header = {.magic = proto::kMagic,
                   .version = proto::kVersion,
                   .type = static_cast<std::uint8_t>(proto::Type::Telemetry),
                   .leg_id = cfg::kLegId,
                   .flags = 0,
                   .seq = ++seq,
                   .t_ms = k_uptime_get_32()},
        .pos_rad = {snap.pos_rad[0], snap.pos_rad[1], snap.pos_rad[2]},
        .current_a = {snap.current_a[0], snap.current_a[1], snap.current_a[2]},
        .fault_flags = snap.fault_flags,
        .lost_packets = g.lost_packets.load(),
        .crc_errors = g.crc_errors.load(),
        .armed = snap.armed,
        .state = snap.state,
        .crc = 0};
    proto::seal(p);

    zsock_sendto(sock, &p, sizeof(p), 0,
                 reinterpret_cast<const sockaddr*>(&master), sizeof(master));

    k_sleep(K_MSEC(cfg::kTelemetryPeriodMs));
  }
}

}  // namespace

// Outside the anonymous namespace so shared.hpp's tx_tid names this thread.
K_THREAD_DEFINE(tx_tid, 4096, tx_main, NULL, NULL, NULL, 7, 0, 0);

}  // namespace leg
```
